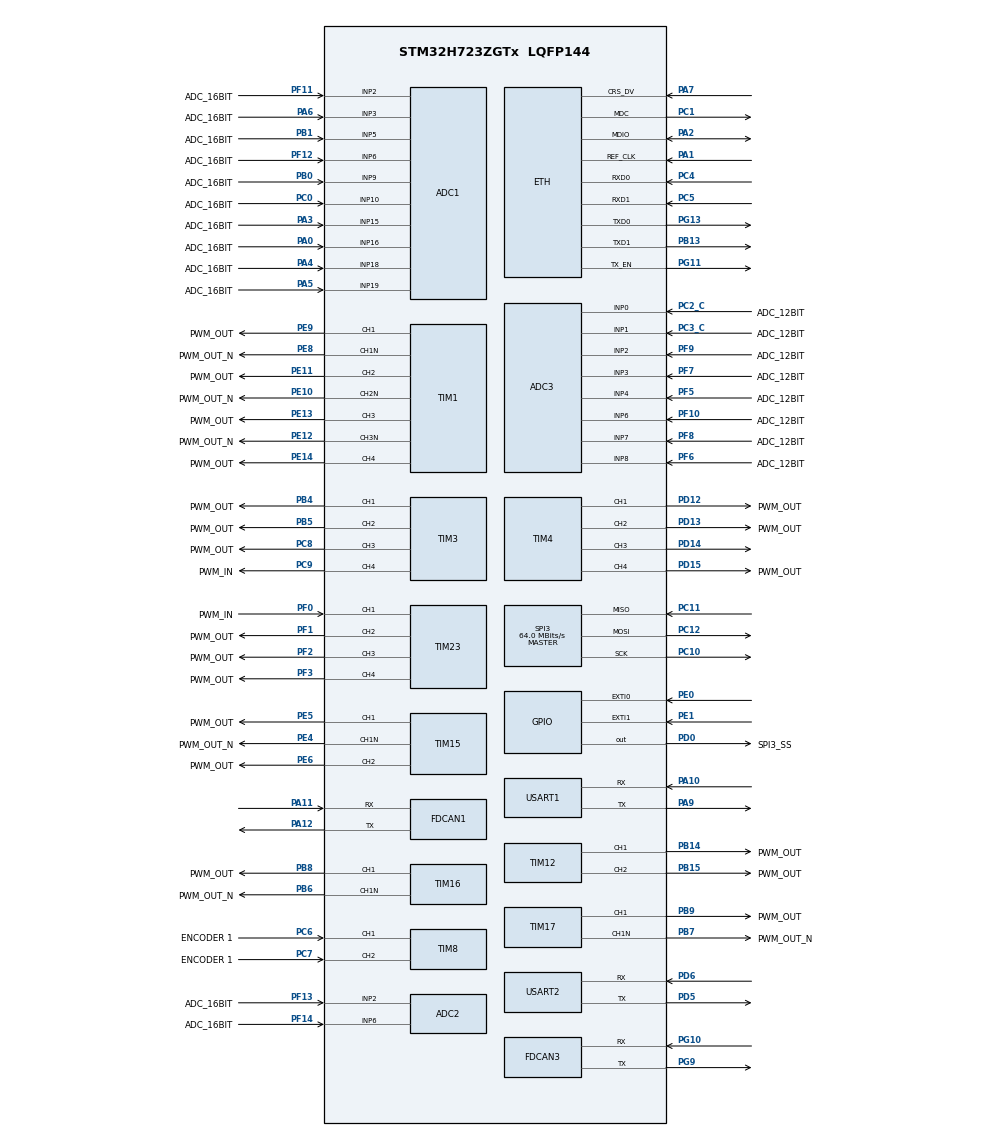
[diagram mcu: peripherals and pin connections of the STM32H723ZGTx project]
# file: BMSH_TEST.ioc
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ADC1.Channel-1\#ChannelRegularConversion=ADC_CHANNEL_2
ADC1.Channel-10\#ChannelRegularConversion=ADC_CHANNEL_19
ADC1.Channel-2\#ChannelRegularConversion=ADC_CHANNEL_3
ADC1.Channel-3\#ChannelRegularConversion=ADC_CHANNEL_5
ADC1.Channel-4\#ChannelRegularConversion=ADC_CHANNEL_6
ADC1.Channel-5\#ChannelRegularConversion=ADC_CHANNEL_9
ADC1.Channel-6\#ChannelRegularConversion=ADC_CHANNEL_10
ADC1.Channel-7\#ChannelRegularConversion=ADC_CHANNEL_15
ADC1.Channel-8\#ChannelRegularConversion=ADC_CHANNEL_16
ADC1.Channel-9\#ChannelRegularConversion=ADC_CHANNEL_18
ADC1.ConversionDataManagement=ADC_CONVERSIONDATA_DMA_CIRCULAR
ADC1.EOCSelection=ADC_EOC_SEQ_CONV
ADC1.ExternalTrigConv=ADC_EXTERNALTRIG_LPTIM1_OUT
ADC1.NbrOfConversion=10
ADC1.NbrOfConversionFlag=1
ADC1.OffsetNumber-1\#ChannelRegularConversion=ADC_OFFSET_NONE
ADC1.OffsetNumber-10\#ChannelRegularConversion=ADC_OFFSET_NONE
ADC1.OffsetNumber-2\#ChannelRegularConversion=ADC_OFFSET_NONE
ADC1.OffsetNumber-3\#ChannelRegularConversion=ADC_OFFSET_NONE
ADC1.OffsetNumber-4\#ChannelRegularConversion=ADC_OFFSET_NONE
ADC1.OffsetNumber-5\#ChannelRegularConversion=ADC_OFFSET_NONE
ADC1.OffsetNumber-6\#ChannelRegularConversion=ADC_OFFSET_NONE
ADC1.OffsetNumber-7\#ChannelRegularConversion=ADC_OFFSET_NONE
ADC1.OffsetNumber-8\#ChannelRegularConversion=ADC_OFFSET_NONE
ADC1.OffsetNumber-9\#ChannelRegularConversion=ADC_OFFSET_NONE
ADC1.OffsetSignedSaturation-1\#ChannelRegularConversion=DISABLE
ADC1.OffsetSignedSaturation-10\#ChannelRegularConversion=DISABLE
ADC1.OffsetSignedSaturation-2\#ChannelRegularConversion=DISABLE
ADC1.OffsetSignedSaturation-3\#ChannelRegularConversion=DISABLE
ADC1.OffsetSignedSaturation-4\#ChannelRegularConversion=DISABLE
ADC1.OffsetSignedSaturation-5\#ChannelRegularConversion=DISABLE
ADC1.OffsetSignedSaturation-6\#ChannelRegularConversion=DISABLE
ADC1.OffsetSignedSaturation-7\#ChannelRegularConversion=DISABLE
ADC1.OffsetSignedSaturation-8\#ChannelRegularConversion=DISABLE
ADC1.OffsetSignedSaturation-9\#ChannelRegularConversion=DISABLE
ADC1.Rank-1\#ChannelRegularConversion=1
ADC1.Rank-10\#ChannelRegularConversion=10
ADC1.Rank-2\#ChannelRegularConversion=2
ADC1.Rank-3\#ChannelRegularConversion=3
ADC1.Rank-4\#ChannelRegularConversion=4
ADC1.Rank-5\#ChannelRegularConversion=5
ADC1.Rank-6\#ChannelRegularConversion=6
ADC1.Rank-7\#ChannelRegularConversion=7
ADC1.Rank-8\#ChannelRegularConversion=8
ADC1.Rank-9\#ChannelRegularConversion=9
ADC1.SamplingTime-1\#ChannelRegularConversion=ADC_SAMPLETIME_1CYCLE_5
ADC1.SamplingTime-10\#ChannelRegularConversion=ADC_SAMPLETIME_1CYCLE_5
ADC1.SamplingTime-2\#ChannelRegularConversion=ADC_SAMPLETIME_1CYCLE_5
ADC1.SamplingTime-3\#ChannelRegularConversion=ADC_SAMPLETIME_1CYCLE_5
ADC1.SamplingTime-4\#ChannelRegularConversion=ADC_SAMPLETIME_1CYCLE_5
ADC1.SamplingTime-5\#ChannelRegularConversion=ADC_SAMPLETIME_1CYCLE_5
ADC1.SamplingTime-6\#ChannelRegularConversion=ADC_SAMPLETIME_1CYCLE_5
ADC1.SamplingTime-7\#ChannelRegularConversion=ADC_SAMPLETIME_1CYCLE_5
ADC1.SamplingTime-8\#ChannelRegularConversion=ADC_SAMPLETIME_1CYCLE_5
ADC1.SamplingTime-9\#ChannelRegularConversion=ADC_SAMPLETIME_1CYCLE_5
ADC1.master=1
ADC2.Channel-0\#ChannelRegularConversion=ADC_CHANNEL_2
ADC2.Channel-1\#ChannelRegularConversion=ADC_CHANNEL_6
ADC2.ConversionDataManagement=ADC_CONVERSIONDATA_DMA_CIRCULAR
ADC2.EOCSelection=ADC_EOC_SEQ_CONV
ADC2.ExternalTrigConv=ADC_EXTERNALTRIG_LPTIM2_OUT
ADC2.NbrOfConversion=2
ADC2.NbrOfConversionFlag=1
ADC2.OffsetNumber-0\#ChannelRegularConversion=ADC_OFFSET_NONE
ADC2.OffsetNumber-1\#ChannelRegularConversion=ADC_OFFSET_NONE
ADC2.OffsetSignedSaturation-0\#ChannelRegularConversion=DISABLE
ADC2.OffsetSignedSaturation-1\#ChannelRegularConversion=DISABLE
ADC2.Rank-0\#ChannelRegularConversion=1
ADC2.Rank-1\#ChannelRegularConversion=2
ADC2.SamplingTime-0\#ChannelRegularConversion=ADC_SAMPLETIME_1CYCLE_5
ADC2.SamplingTime-1\#ChannelRegularConversion=ADC_SAMPLETIME_1CYCLE_5
ADC3.Channel-0\#ChannelRegularConversion=ADC_CHANNEL_0
ADC3.Channel-1\#ChannelRegularConversion=ADC_CHANNEL_1
ADC3.Channel-2\#ChannelRegularConversion=ADC_CHANNEL_2
ADC3.Channel-3\#ChannelRegularConversion=ADC_CHANNEL_3
ADC3.Channel-4\#ChannelRegularConversion=ADC_CHANNEL_4
ADC3.Channel-5\#ChannelRegularConversion=ADC_CHANNEL_6
ADC3.Channel-6\#ChannelRegularConversion=ADC_CHANNEL_7
ADC3.Channel-7\#ChannelRegularConversion=ADC_CHANNEL_8
ADC3.ConversionDataManagement=ADC_CONVERSIONDATA_DMA_CIRCULAR
ADC3.DMAContinuousRequests=ENABLE
ADC3.ExternalTrigConv=ADC_EXTERNALTRIG_LPTIM3_OUT
ADC3.NbrOfConversion=8
ADC3.NbrOfConversionFlag=1
ADC3.OffsetNumber-0\#ChannelRegularConversion=ADC_OFFSET_NONE
ADC3.OffsetNumber-1\#ChannelRegularConversion=ADC_OFFSET_NONE
ADC3.OffsetNumber-2\#ChannelRegularConversion=ADC_OFFSET_NONE
ADC3.OffsetNumber-3\#ChannelRegularConversion=ADC_OFFSET_NONE
ADC3.OffsetNumber-4\#ChannelRegularConversion=ADC_OFFSET_NONE
ADC3.OffsetNumber-5\#ChannelRegularConversion=ADC_OFFSET_NONE
ADC3.OffsetNumber-6\#ChannelRegularConversion=ADC_OFFSET_NONE
ADC3.OffsetNumber-7\#ChannelRegularConversion=ADC_OFFSET_NONE
ADC3.OffsetSaturation-0\#ChannelRegularConversion=DISABLE
ADC3.OffsetSign-0\#ChannelRegularConversion=ADC3_OFFSET_SIGN_NEGATIVE
ADC3.OffsetSign-1\#ChannelRegularConversion=ADC3_OFFSET_SIGN_NEGATIVE
ADC3.OffsetSign-2\#ChannelRegularConversion=ADC3_OFFSET_SIGN_NEGATIVE
ADC3.OffsetSign-3\#ChannelRegularConversion=ADC3_OFFSET_SIGN_NEGATIVE
ADC3.OffsetSign-4\#ChannelRegularConversion=ADC3_OFFSET_SIGN_NEGATIVE
ADC3.OffsetSign-5\#ChannelRegularConversion=ADC3_OFFSET_SIGN_NEGATIVE
ADC3.OffsetSign-6\#ChannelRegularConversion=ADC3_OFFSET_SIGN_NEGATIVE
ADC3.OffsetSign-7\#ChannelRegularConversion=ADC3_OFFSET_SIGN_NEGATIVE
ADC3.Rank-0\#ChannelRegularConversion=1
ADC3.Rank-1\#ChannelRegularConversion=2
ADC3.Rank-2\#ChannelRegularConversion=3
ADC3.Rank-3\#ChannelRegularConversion=4
ADC3.Rank-4\#ChannelRegularConversion=5
ADC3.Rank-5\#ChannelRegularConversion=6
ADC3.Rank-6\#ChannelRegularConversion=7
ADC3.Rank-7\#ChannelRegularConversion=8
ADC3.SamplingTime-0\#ChannelRegularConversion=ADC3_SAMPLETIME_2CYCLES_5
ADC3.SamplingTime-1\#ChannelRegularConversion=ADC3_SAMPLETIME_2CYCLES_5
ADC3.SamplingTime-2\#ChannelRegularConversion=ADC3_SAMPLETIME_2CYCLES_5
ADC3.SamplingTime-3\#ChannelRegularConversion=ADC3_SAMPLETIME_2CYCLES_5
ADC3.SamplingTime-4\#ChannelRegularConversion=ADC3_SAMPLETIME_2CYCLES_5
ADC3.SamplingTime-5\#ChannelRegularConversion=ADC3_SAMPLETIME_2CYCLES_5
ADC3.SamplingTime-6\#ChannelRegularConversion=ADC3_SAMPLETIME_2CYCLES_5
ADC3.SamplingTime-7\#ChannelRegularConversion=ADC3_SAMPLETIME_2CYCLES_5
Dma.ADC1.0.Direction=DMA_PERIPH_TO_MEMORY
Dma.ADC1.0.EventEnable=DISABLE
Dma.ADC1.0.FIFOMode=DMA_FIFOMODE_DISABLE
Dma.ADC1.0.Instance=DMA1_Stream0
Dma.ADC1.0.MemDataAlignment=DMA_MDATAALIGN_HALFWORD
Dma.ADC1.0.MemInc=DMA_MINC_ENABLE
Dma.ADC1.0.Mode=DMA_CIRCULAR
Dma.ADC1.0.PeriphDataAlignment=DMA_PDATAALIGN_HALFWORD
Dma.ADC1.0.PeriphInc=DMA_PINC_DISABLE
Dma.ADC1.0.Polarity=HAL_DMAMUX_REQ_GEN_RISING
Dma.ADC1.0.Priority=DMA_PRIORITY_LOW
Dma.ADC1.0.RequestNumber=1
Dma.ADC1.0.SignalID=NONE
Dma.ADC1.0.SyncEnable=DISABLE
Dma.ADC1.0.SyncPolarity=HAL_DMAMUX_SYNC_NO_EVENT
Dma.ADC1.0.SyncRequestNumber=1
Dma.ADC1.0.SyncSignalID=NONE
Dma.ADC2.1.Direction=DMA_PERIPH_TO_MEMORY
Dma.ADC2.1.EventEnable=DISABLE
Dma.ADC2.1.FIFOMode=DMA_FIFOMODE_DISABLE
Dma.ADC2.1.Instance=DMA1_Stream1
Dma.ADC2.1.MemDataAlignment=DMA_MDATAALIGN_HALFWORD
Dma.ADC2.1.MemInc=DMA_MINC_ENABLE
Dma.ADC2.1.Mode=DMA_CIRCULAR
Dma.ADC2.1.PeriphDataAlignment=DMA_PDATAALIGN_HALFWORD
Dma.ADC2.1.PeriphInc=DMA_PINC_DISABLE
Dma.ADC2.1.Polarity=HAL_DMAMUX_REQ_GEN_RISING
Dma.ADC2.1.Priority=DMA_PRIORITY_LOW
Dma.ADC2.1.RequestNumber=1
Dma.ADC2.1.SignalID=NONE
Dma.ADC2.1.SyncEnable=DISABLE
Dma.ADC2.1.SyncPolarity=HAL_DMAMUX_SYNC_NO_EVENT
Dma.ADC2.1.SyncRequestNumber=1
Dma.ADC2.1.SyncSignalID=NONE
Dma.ADC3.2.Direction=DMA_PERIPH_TO_MEMORY
Dma.ADC3.2.EventEnable=DISABLE
Dma.ADC3.2.FIFOMode=DMA_FIFOMODE_DISABLE
Dma.ADC3.2.Instance=DMA1_Stream2
Dma.ADC3.2.MemDataAlignment=DMA_MDATAALIGN_HALFWORD
Dma.ADC3.2.MemInc=DMA_MINC_ENABLE
Dma.ADC3.2.Mode=DMA_CIRCULAR
Dma.ADC3.2.PeriphDataAlignment=DMA_PDATAALIGN_HALFWORD
Dma.ADC3.2.PeriphInc=DMA_PINC_DISABLE
Dma.ADC3.2.Polarity=HAL_DMAMUX_REQ_GEN_RISING
Dma.ADC3.2.Priority=DMA_PRIORITY_LOW
Dma.ADC3.2.RequestNumber=1
Dma.ADC3.2.SignalID=NONE
Dma.ADC3.2.SyncEnable=DISABLE
Dma.ADC3.2.SyncPolarity=HAL_DMAMUX_SYNC_NO_EVENT
Dma.ADC3.2.SyncRequestNumber=1
Dma.ADC3.2.SyncSignalID=NONE
Dma.Request0=ADC1
Dma.Request1=ADC2
Dma.Request2=ADC3
ETH.MediaInterface=HAL_ETH_RMII_MODE
FDCAN1.CalculateBaudRateNominal=1718750
FDCAN1.CalculateTimeBitNominal=581
FDCAN1.CalculateTimeQuantumNominal=116.36363636363636
FDCAN3.CalculateBaudRateNominal=1718750
FDCAN3.CalculateTimeBitNominal=581
FDCAN3.CalculateTimeQuantumNominal=116.36363636363636
Mcu.Family=STM32H7
Mcu.Name=STM32H723ZGTx
Mcu.Package=LQFP144
NVIC.DMA1_Stream0_IRQn=true\:0\:0\:false\:false\:true\:false\:true\:true
NVIC.DMA1_Stream1_IRQn=true\:0\:0\:false\:false\:true\:false\:true\:true
NVIC.DMA1_Stream2_IRQn=true\:0\:0\:false\:false\:true\:false\:true\:true
NVIC.EXTI0_IRQn=true\:0\:0\:false\:false\:true\:true\:true\:true
NVIC.EXTI1_IRQn=true\:0\:0\:false\:false\:true\:true\:true\:true
NVIC.LPTIM1_IRQn=true\:0\:0\:false\:false\:true\:true\:true\:true
NVIC.LPTIM2_IRQn=true\:0\:0\:false\:false\:true\:true\:true\:true
NVIC.LPTIM3_IRQn=true\:0\:0\:false\:false\:true\:true\:true\:true
NVIC.PriorityGroup=NVIC_PRIORITYGROUP_4
NVIC.TIM24_IRQn=true\:0\:0\:false\:false\:true\:true\:true\:true
NVIC.TIM2_IRQn=true\:0\:0\:false\:false\:true\:true\:true\:true
NVIC.TIM5_IRQn=true\:0\:0\:false\:false\:true\:true\:true\:true
NVIC.TIM6_DAC_IRQn=true\:0\:0\:false\:false\:true\:true\:true\:true
PA0.GPIO_Label=ADC_16BIT
PA0.Mode=IN16-Single-Ended
PA0.Signal=ADC1_INP16
PA1.Mode=RMII
PA1.Signal=ETH_REF_CLK
PA10.Mode=Asynchronous
PA10.Signal=USART1_RX
PA11.Mode=FDCAN_Activate
PA11.Signal=FDCAN1_RX
PA12.Mode=FDCAN_Activate
PA12.Signal=FDCAN1_TX
PA13(JTMS/SWDIO).Mode=JTAG_4_pins
PA13(JTMS/SWDIO).Signal=DEBUG_JTMS-SWDIO
PA14(JTCK/SWCLK).Mode=JTAG_4_pins
PA14(JTCK/SWCLK).Signal=DEBUG_JTCK-SWCLK
PA15(JTDI).Mode=JTAG_4_pins
PA15(JTDI).Signal=DEBUG_JTDI
PA2.Mode=RMII
PA2.Signal=ETH_MDIO
PA3.GPIO_Label=ADC_16BIT
PA3.Signal=ADCx_INP15
PA4.GPIO_Label=ADC_16BIT
PA4.Signal=ADCx_INP18
PA5.GPIO_Label=ADC_16BIT
PA5.Signal=ADCx_INP19
PA6.GPIO_Label=ADC_16BIT
PA6.Signal=ADCx_INP3
PA7.Mode=RMII
PA7.Signal=ETH_CRS_DV
PA9.Mode=Asynchronous
PA9.Signal=USART1_TX
PB0.GPIO_Label=ADC_16BIT
PB0.Signal=ADCx_INP9
PB1.GPIO_Label=ADC_16BIT
PB1.Signal=ADCx_INP5
PB13.Mode=RMII
PB13.Signal=ETH_TXD1
PB14.GPIO_Label=PWM_OUT
PB14.Signal=S_TIM12_CH1
PB15.GPIO_Label=PWM_OUT
PB15.Signal=S_TIM12_CH2
PB3(JTDO/TRACESWO).Mode=JTAG_4_pins
PB3(JTDO/TRACESWO).Signal=DEBUG_JTDO-SWO
PB4(NJTRST).GPIO_Label=PWM_OUT
PB4(NJTRST).Signal=S_TIM3_CH1
PB5.GPIO_Label=PWM_OUT
PB5.Signal=S_TIM3_CH2
PB6.GPIO_Label=PWM_OUT_N
PB6.Mode=PWM Generation1 CH1 CH1N
PB6.Signal=TIM16_CH1N
PB7.GPIO_Label=PWM_OUT_N
PB7.Mode=PWM Generation1 CH1 CH1N
PB7.Signal=TIM17_CH1N
PB8.GPIO_Label=PWM_OUT
PB8.Signal=S_TIM16_CH1
PB9.GPIO_Label=PWM_OUT
PB9.Signal=S_TIM17_CH1
PC0.GPIO_Label=ADC_16BIT
PC0.Signal=ADCx_INP10
PC1.Mode=RMII
PC1.Signal=ETH_MDC
PC10.Mode=Full_Duplex_Master
PC10.Signal=SPI3_SCK
PC11.Mode=Full_Duplex_Master
PC11.Signal=SPI3_MISO
PC12.Mode=Full_Duplex_Master
PC12.Signal=SPI3_MOSI
PC14-OSC32_IN.GPIO_Label=RTC_IN
PC14-OSC32_IN.Mode=LSE-External-Oscillator
PC14-OSC32_IN.Signal=RCC_OSC32_IN
PC15-OSC32_OUT.GPIO_Label=RTC_OUT
PC15-OSC32_OUT.Mode=LSE-External-Oscillator
PC15-OSC32_OUT.Signal=RCC_OSC32_OUT
PC2_C.GPIO_Label=ADC_12BIT
PC2_C.Mode=IN0-Single-Ended
PC2_C.Signal=ADC3_INP0
PC3_C.GPIO_Label=ADC_12BIT
PC3_C.Mode=IN1-Single-Ended
PC3_C.Signal=ADC3_INP1
PC4.Mode=RMII
PC4.Signal=ETH_RXD0
PC5.Mode=RMII
PC5.Signal=ETH_RXD1
PC6.GPIO_Label=ENCODER 1
PC6.Signal=S_TIM8_CH1
PC7.GPIO_Label=ENCODER 1
PC7.Signal=S_TIM8_CH2
PC8.GPIO_Label=PWM_OUT
PC8.Signal=S_TIM3_CH3
PC9.GPIO_Label=PWM_IN
PC9.Signal=S_TIM3_CH4
PD0.GPIO_Label=SPI3_SS
PD0.Signal=GPIO_Output
PD12.GPIO_Label=PWM_OUT
PD12.Signal=S_TIM4_CH1
PD13.GPIO_Label=PWM_OUT
PD13.Signal=S_TIM4_CH2
PD14.Signal=S_TIM4_CH3
PD15.GPIO_Label=PWM_OUT
PD15.Signal=S_TIM4_CH4
PD5.Mode=Asynchronous
PD5.Signal=USART2_TX
PD6.Mode=Asynchronous
PD6.Signal=USART2_RX
PE0.Signal=GPXTI0
PE1.Signal=GPXTI1
PE10.GPIO_Label=PWM_OUT_N
PE10.Mode=PWM Generation2 CH2 CH2N
PE10.Signal=TIM1_CH2N
PE11.GPIO_Label=PWM_OUT
PE11.Signal=S_TIM1_CH2
PE12.GPIO_Label=PWM_OUT_N
PE12.Mode=PWM Generation3 CH3 CH3N
PE12.Signal=TIM1_CH3N
PE13.GPIO_Label=PWM_OUT
PE13.Signal=S_TIM1_CH3
PE14.GPIO_Label=PWM_OUT
PE14.Signal=S_TIM1_CH4
PE4.GPIO_Label=PWM_OUT_N
PE4.Mode=PWM Generation1 CH1 CH1N
PE4.Signal=TIM15_CH1N
PE5.GPIO_Label=PWM_OUT
PE5.Signal=S_TIM15_CH1
PE6.GPIO_Label=PWM_OUT
PE6.Signal=S_TIM15_CH2
PE8.GPIO_Label=PWM_OUT_N
PE8.Mode=PWM Generation1 CH1 CH1N
PE8.Signal=TIM1_CH1N
PE9.GPIO_Label=PWM_OUT
PE9.Signal=S_TIM1_CH1
PF0.GPIO_Label=PWM_IN
PF0.Mode=Input_Capture1_from_TI1
PF0.Signal=TIM23_CH1
PF1.GPIO_Label=PWM_OUT
PF1.Signal=S_TIM23_CH2
PF10.GPIO_Label=ADC_12BIT
PF10.Mode=IN6-Single-Ended
PF10.Signal=ADC3_INP6
PF11.GPIO_Label=ADC_16BIT
PF11.Mode=IN2-Single-Ended
PF11.Signal=ADC1_INP2
PF12.GPIO_Label=ADC_16BIT
PF12.Mode=IN6-Single-Ended
PF12.Signal=ADC1_INP6
PF13.GPIO_Label=ADC_16BIT
PF13.Mode=IN2-Single-Ended
PF13.Signal=ADC2_INP2
PF14.GPIO_Label=ADC_16BIT
PF14.Mode=IN6-Single-Ended
PF14.Signal=ADC2_INP6
PF2.GPIO_Label=PWM_OUT
PF2.Signal=S_TIM23_CH3
PF3.GPIO_Label=PWM_OUT
PF3.Signal=S_TIM23_CH4
PF5.GPIO_Label=ADC_12BIT
PF5.Mode=IN4-Single-Ended
PF5.Signal=ADC3_INP4
PF6.GPIO_Label=ADC_12BIT
PF6.Mode=IN8-Single-Ended
PF6.Signal=ADC3_INP8
PF7.GPIO_Label=ADC_12BIT
PF7.Mode=IN3-Single-Ended
PF7.Signal=ADC3_INP3
PF8.GPIO_Label=ADC_12BIT
PF8.Mode=IN7-Single-Ended
PF8.Signal=ADC3_INP7
PF9.GPIO_Label=ADC_12BIT
PF9.Mode=IN2-Single-Ended
PF9.Signal=ADC3_INP2
PG10.Mode=FDCAN_Activate
PG10.Signal=FDCAN3_RX
PG11.Mode=RMII
PG11.Signal=ETH_TX_EN
PG13.Mode=RMII
PG13.Signal=ETH_TXD0
PG9.Mode=FDCAN_Activate
PG9.Signal=FDCAN3_TX
PH0-OSC_IN.GPIO_Label=HSE_IN
PH0-OSC_IN.Mode=HSE-External-Oscillator
PH0-OSC_IN.Signal=RCC_OSC_IN
PH1-OSC_OUT.GPIO_Label=HSE_OUT
PH1-OSC_OUT.Mode=HSE-External-Oscillator
PH1-OSC_OUT.Signal=RCC_OSC_OUT
ProjectManager.HeapSize=0x200
ProjectManager.StackSize=0x400
ProjectManager.TargetToolchain=STM32CubeIDE
RCC.ADCFreq_Value=96000000
RCC.APB1Freq_Value=137500000
RCC.APB2Freq_Value=137500000
RCC.APB3Freq_Value=137500000
RCC.APB4Freq_Value=137500000
RCC.CortexFreq_Value=550000000
RCC.D1PPRE=RCC_APB3_DIV2
RCC.D2PPRE1=RCC_APB1_DIV2
RCC.D2PPRE2=RCC_APB2_DIV2
RCC.D3PPRE=RCC_APB4_DIV2
RCC.DIVM1=4
RCC.DIVM2=1
RCC.DIVM3=8
RCC.DIVN1=275
RCC.DIVN2=24
RCC.DIVN3=256
RCC.DIVP1=1
RCC.DIVQ1=4
RCC.EnbaleCSS=false
RCC.FLatency-AdvancedSettings=FLASH_LATENCY_3
RCC.HCLKFreq_Value=275000000
RCC.HPRE=RCC_HCLK_DIV2
RCC.HSE_VALUE=8000000
RCC.PLL1_VCI_Range-AdvancedSettings=RCC_PLL1VCIRANGE_0
RCC.PLL1_VCO_SEL-AdvancedSettings=RCC_PLL1VCOMEDIUM
RCC.PLL2_VCO_SEL-AdvancedSettings=RCC_PLL2VCOMEDIUM
RCC.PLL3_VCO_SEL-AdvancedSettings=RCC_PLL3VCOWIDE
RCC.PLLFRACN=0
RCC.PLLSourceVirtual=RCC_PLLSOURCE_HSE
RCC.SPI123CLockSelection=RCC_SPI123CLKSOURCE_PLL3
RCC.SYSCLKFreq_VALUE=550000000
RCC.SYSCLKSource=RCC_SYSCLKSOURCE_PLLCLK
RCC.USBCLockSelection=RCC_USBCLKSOURCE_HSI48
RCC.USBFreq_Value=48000000
SH.ADCx_INP10.0=ADC1_INP10,IN10-Single-Ended
SH.ADCx_INP15.0=ADC1_INP15,IN15-Single-Ended
SH.ADCx_INP18.0=ADC1_INP18,IN18-Single-Ended
SH.ADCx_INP19.0=ADC1_INP19,IN19-Single-Ended
SH.ADCx_INP3.0=ADC1_INP3,IN3-Single-Ended
SH.ADCx_INP5.0=ADC1_INP5,IN5-Single-Ended
SH.ADCx_INP9.0=ADC1_INP9,IN9-Single-Ended
SH.S_TIM12_CH1.0=TIM12_CH1,PWM Generation1 CH1
SH.S_TIM12_CH2.0=TIM12_CH2,PWM Generation2 CH2
SH.S_TIM15_CH1.0=TIM15_CH1,PWM Generation1 CH1 CH1N
SH.S_TIM15_CH2.0=TIM15_CH2,PWM Generation2 CH2
SH.S_TIM16_CH1.0=TIM16_CH1,PWM Generation1 CH1 CH1N
SH.S_TIM17_CH1.0=TIM17_CH1,PWM Generation1 CH1 CH1N
SH.S_TIM1_CH1.0=TIM1_CH1,PWM Generation1 CH1 CH1N
SH.S_TIM1_CH2.0=TIM1_CH2,PWM Generation2 CH2 CH2N
SH.S_TIM1_CH3.0=TIM1_CH3,PWM Generation3 CH3 CH3N
SH.S_TIM1_CH4.0=TIM1_CH4,PWM Generation4 CH4
SH.S_TIM23_CH2.0=TIM23_CH2,PWM Generation2 CH2
SH.S_TIM23_CH3.0=TIM23_CH3,PWM Generation3 CH3
SH.S_TIM23_CH4.0=TIM23_CH4,PWM Generation4 CH4
SH.S_TIM3_CH1.0=TIM3_CH1,PWM Generation1 CH1
SH.S_TIM3_CH2.0=TIM3_CH2,PWM Generation2 CH2
SH.S_TIM3_CH3.0=TIM3_CH3,PWM Generation3 CH3
SH.S_TIM3_CH4.0=TIM3_CH4,PWM Generation4 CH4
SH.S_TIM4_CH1.0=TIM4_CH1,PWM Generation1 CH1
SH.S_TIM4_CH2.0=TIM4_CH2,PWM Generation2 CH2
SH.S_TIM4_CH3.0=TIM4_CH3,PWM Generation3 CH3
SH.S_TIM4_CH4.0=TIM4_CH4,PWM Generation4 CH4
SH.S_TIM8_CH1.0=TIM8_CH1,Encoder_Interface
SH.S_TIM8_CH2.0=TIM8_CH2,Encoder_Interface
SPI3.CalculateBaudRate=64.0 MBits/s
SPI3.Direction=SPI_DIRECTION_2LINES
SPI3.Mode=SPI_MODE_MASTER
SPI3.VirtualType=VM_MASTER
TIM1.Channel-PWM\ Generation1\ CH1\ CH1N=TIM_CHANNEL_1
TIM1.Channel-PWM\ Generation2\ CH2\ CH2N=TIM_CHANNEL_2
TIM1.Channel-PWM\ Generation3\ CH3\ CH3N=TIM_CHANNEL_3
TIM1.Channel-PWM\ Generation4\ CH4=TIM_CHANNEL_4
TIM12.Channel-PWM\ Generation1\ CH1=TIM_CHANNEL_1
TIM12.Channel-PWM\ Generation2\ CH2=TIM_CHANNEL_2
TIM15.Channel-PWM\ Generation1\ CH1\ CH1N=TIM_CHANNEL_1
TIM15.Channel-PWM\ Generation2\ CH2=TIM_CHANNEL_2
TIM16.Channel=TIM_CHANNEL_1
TIM17.Channel=TIM_CHANNEL_1
TIM23.Channel-Input_Capture1_from_TI1=TIM_CHANNEL_1
TIM23.Channel-PWM\ Generation2\ CH2=TIM_CHANNEL_2
TIM23.Channel-PWM\ Generation3\ CH3=TIM_CHANNEL_3
TIM23.Channel-PWM\ Generation4\ CH4=TIM_CHANNEL_4
TIM3.Channel-PWM\ Generation1\ CH1=TIM_CHANNEL_1
TIM3.Channel-PWM\ Generation2\ CH2=TIM_CHANNEL_2
TIM3.Channel-PWM\ Generation3\ CH3=TIM_CHANNEL_3
TIM3.Channel-PWM\ Generation4\ CH4=TIM_CHANNEL_4
TIM4.Channel-PWM\ Generation1\ CH1=TIM_CHANNEL_1
TIM4.Channel-PWM\ Generation2\ CH2=TIM_CHANNEL_2
TIM4.Channel-PWM\ Generation3\ CH3=TIM_CHANNEL_3
TIM4.Channel-PWM\ Generation4\ CH4=TIM_CHANNEL_4
USART1.VirtualMode-Asynchronous=VM_ASYNC
USART2.VirtualMode-Asynchronous=VM_ASYNC
VP_CORDIC_VS_CORDIC.Mode=CORDIC_Activate
VP_FMAC_VS_FMAC.Mode=FMAC_Activate
VP_LPTIM1_VS_LPTIM_counterModeInternalClock.Mode=Counts__internal_clock_event_00
VP_LPTIM2_VS_LPTIM_counterModeInternalClock.Mode=Counts__internal_clock_event_00
VP_LPTIM3_VS_LPTIM_counterModeInternalClock.Mode=Counts__internal_clock_event_00
VP_RTC_VS_RTC_Activate.Mode=RTC_Enabled
VP_TIM16_VS_ClockSourceINT.Mode=Enable_Timer
VP_TIM17_VS_ClockSourceINT.Mode=Enable_Timer
VP_TIM24_VS_ClockSourceINT.Mode=Internal
VP_TIM2_VS_ClockSourceINT.Mode=Internal
VP_TIM5_VS_ClockSourceINT.Mode=Internal
VP_TIM6_VS_ClockSourceINT.Mode=Enable_Timer
board=NUCLEO-H723ZG

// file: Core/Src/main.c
/* USER CODE BEGIN Header */
/**
  ******************************************************************************
  * @file           : main.c
  * @brief          : Main program body
  ******************************************************************************
  * @attention
  *
  * Copyright (c) 2022 STMicroelectronics.
  * All rights reserved.
  *
  * This software is licensed under terms that can be found in the LICENSE file
  * in the root directory of this software component.
  * If no LICENSE file comes with this software, it is provided AS-IS.
  *
  ******************************************************************************
  */
/* USER CODE END Header */
#include "main.h"
#include "adc.h"
#include "cordic.h"
#include "dma.h"
#include "fdcan.h"
#include "fmac.h"
#include "lptim.h"
#include "rtc.h"
#include "spi.h"
#include "tim.h"
#include "usart.h"
#include "gpio.h"

/* USER CODE BEGIN Includes */

#include "ST-LIB.hpp"
#include "BMSH/BMSH.hpp"

/* USER CODE END Includes */

void SystemClock_Config(void);
void PeriphCommonClock_Config(void);

int main(void)
{

  /* MCU Configuration--------------------------------------------------------*/

  /* Reset of all peripherals, Initializes the Flash interface and the Systick. */
  HAL_Init();

  /* Configure the system clock */
  SystemClock_Config();

/* Configure the peripherals common clocks */
  PeriphCommonClock_Config();

  /* USER CODE BEGIN SysInit */
  uint8_t spi_instance = SPI::inscribe(SPI::spi3).value_or(69);

  /* USER CODE END SysInit */

  /* Initialize all configured peripherals */
  MX_GPIO_Init();
  MX_ADC1_Init();
  MX_ADC2_Init();
  MX_ADC3_Init();
  MX_FDCAN1_Init();
  MX_TIM1_Init();
  MX_TIM3_Init();
  MX_TIM4_Init();
  MX_TIM8_Init();
  MX_TIM12_Init();
  MX_TIM23_Init();
  MX_USART1_UART_Init();
  MX_USART2_UART_Init();
  MX_CORDIC_Init();
  MX_FMAC_Init();
  MX_RTC_Init();
  MX_TIM15_Init();
  MX_TIM16_Init();
  MX_FDCAN3_Init();
  MX_TIM17_Init();
  MX_SPI3_Init();
  MX_LPTIM1_Init();
  MX_LPTIM2_Init();
  MX_DMA_Init();
  MX_LPTIM3_Init();
  MX_TIM2_Init();
  MX_TIM5_Init();
  MX_TIM6_Init();
  MX_TIM24_Init();
  /* USER CODE BEGIN 2 */

  BMSH bmsh = BMSH(spi_instance);
  /* USER CODE END 2 */

  /* Infinite loop */
  while (1)
  {

  }
}

void SystemClock_Config(void)
{
  RCC_OscInitTypeDef RCC_OscInitStruct = {0};
  RCC_ClkInitTypeDef RCC_ClkInitStruct = {0};

  /** Supply configuration update enable
  */
  HAL_PWREx_ConfigSupply(PWR_LDO_SUPPLY);

  /** Configure the main internal regulator output voltage
  */
  __HAL_PWR_VOLTAGESCALING_CONFIG(PWR_REGULATOR_VOLTAGE_SCALE0);

  while(!__HAL_PWR_GET_FLAG(PWR_FLAG_VOSRDY)) {}

  /** Macro to configure the PLL clock source
  */
  __HAL_RCC_PLL_PLLSOURCE_CONFIG(RCC_PLLSOURCE_HSE);

  /** Initializes the RCC Oscillators according to the specified parameters
  * in the RCC_OscInitTypeDef structure.
  */
  RCC_OscInitStruct.OscillatorType = RCC_OSCILLATORTYPE_LSI|RCC_OSCILLATORTYPE_HSE;
  RCC_OscInitStruct.HSEState = RCC_HSE_ON;
  RCC_OscInitStruct.LSIState = RCC_LSI_ON;
  RCC_OscInitStruct.PLL.PLLState = RCC_PLL_ON;
  RCC_OscInitStruct.PLL.PLLSource = RCC_PLLSOURCE_HSE;
  RCC_OscInitStruct.PLL.PLLM = 4;
  RCC_OscInitStruct.PLL.PLLN = 275;
  RCC_OscInitStruct.PLL.PLLP = 1;
  RCC_OscInitStruct.PLL.PLLQ = 4;
  RCC_OscInitStruct.PLL.PLLR = 2;
  RCC_OscInitStruct.PLL.PLLRGE = RCC_PLL1VCIRANGE_1;
  RCC_OscInitStruct.PLL.PLLVCOSEL = RCC_PLL1VCOWIDE;
  RCC_OscInitStruct.PLL.PLLFRACN = 0;
  if (HAL_RCC_OscConfig(&RCC_OscInitStruct) != HAL_OK)
  {
    Error_Handler();
  }

  /** Initializes the CPU, AHB and APB buses clocks
  */
  RCC_ClkInitStruct.ClockType = RCC_CLOCKTYPE_HCLK|RCC_CLOCKTYPE_SYSCLK
                              |RCC_CLOCKTYPE_PCLK1|RCC_CLOCKTYPE_PCLK2
                              |RCC_CLOCKTYPE_D3PCLK1|RCC_CLOCKTYPE_D1PCLK1;
  RCC_ClkInitStruct.SYSCLKSource = RCC_SYSCLKSOURCE_PLLCLK;
  RCC_ClkInitStruct.SYSCLKDivider = RCC_SYSCLK_DIV1;
  RCC_ClkInitStruct.AHBCLKDivider = RCC_HCLK_DIV2;
  RCC_ClkInitStruct.APB3CLKDivider = RCC_APB3_DIV2;
  RCC_ClkInitStruct.APB1CLKDivider = RCC_APB1_DIV2;
  RCC_ClkInitStruct.APB2CLKDivider = RCC_APB2_DIV2;
  RCC_ClkInitStruct.APB4CLKDivider = RCC_APB4_DIV2;

  if (HAL_RCC_ClockConfig(&RCC_ClkInitStruct, FLASH_LATENCY_3) != HAL_OK)
  {
    Error_Handler();
  }
}

void PeriphCommonClock_Config(void)
{
  RCC_PeriphCLKInitTypeDef PeriphClkInitStruct = {0};

  /** Initializes the peripherals clock
  */
  PeriphClkInitStruct.PeriphClockSelection = RCC_PERIPHCLK_ADC;
  PeriphClkInitStruct.PLL2.PLL2M = 1;
  PeriphClkInitStruct.PLL2.PLL2N = 24;
  PeriphClkInitStruct.PLL2.PLL2P = 2;
  PeriphClkInitStruct.PLL2.PLL2Q = 2;
  PeriphClkInitStruct.PLL2.PLL2R = 2;
  PeriphClkInitStruct.PLL2.PLL2RGE = RCC_PLL2VCIRANGE_3;
  PeriphClkInitStruct.PLL2.PLL2VCOSEL = RCC_PLL2VCOWIDE;
  PeriphClkInitStruct.PLL2.PLL2FRACN = 0;
  PeriphClkInitStruct.AdcClockSelection = RCC_ADCCLKSOURCE_PLL2;
  if (HAL_RCCEx_PeriphCLKConfig(&PeriphClkInitStruct) != HAL_OK)
  {
    Error_Handler();
  }
}

void Error_Handler(void)
{
  __disable_irq();
  while (1)
  {
  }
}
